AUTOSAR XML (schema 4-3-0)
package /App_NFC
  sender receiver interface IF_NFC  # NFC SWC Output
    data NFC_STR: type=IDT_NFC_STR
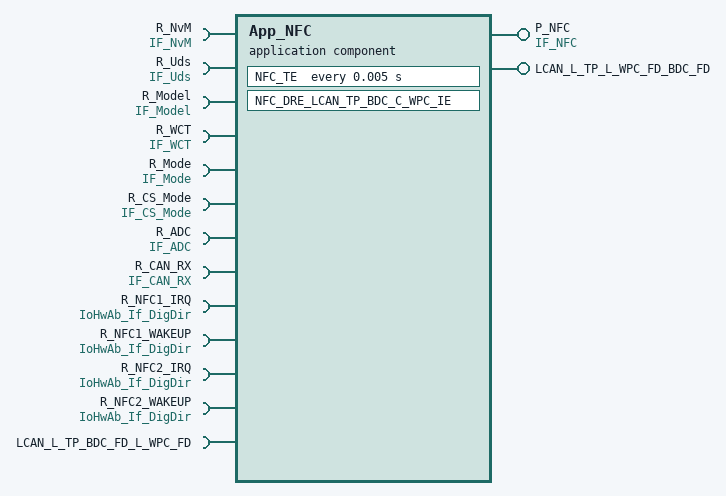
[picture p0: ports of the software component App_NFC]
  application sw component type App_NFC
    provide port P_NFC: nonqueued-sender-com-spec=NFC_STR, provided-interface=IF_NFC
    12 x require port:
      R_NvM: nonqueued-receiver-com-spec=NvM_STR, required-interface=IF_NvM
      R_Uds: nonqueued-receiver-com-spec=Uds_STR, required-interface=IF_Uds
      R_Model: nonqueued-receiver-com-spec=Model_STR, required-interface=IF_Model
      R_WCT: nonqueued-receiver-com-spec=WCT_STR, required-interface=IF_WCT
      R_Mode: nonqueued-receiver-com-spec=Mode_STR, required-interface=IF_Mode
      R_CS_Mode: required-com-specs=[ModeInit, NvMInit, ApplicationInit], required-interface=IF_CS_Mode
      R_ADC: nonqueued-receiver-com-spec=ADC_STR, required-interface=IF_ADC
      R_CAN_RX: nonqueued-receiver-com-spec=CAN_RX_STR, required-interface=IF_CAN_RX
      R_NFC1_IRQ: client-com-spec=ReadDirect, required-interface=IoHwAb_If_DigDir
      R_NFC1_WAKEUP: client-com-spec=WriteDirect, required-interface=IoHwAb_If_DigDir
      R_NFC2_IRQ: client-com-spec=ReadDirect, required-interface=IoHwAb_If_DigDir
      R_NFC2_WAKEUP: client-com-spec=WriteDirect, required-interface=IoHwAb_If_DigDir
    provide port LCAN_L_TP_L_WPC_FD_BDC_FD: queued-sender-com-spec{data-element=LCAN_L_TP_L_WPC_FD_BDC_FD_signal, network-representation=compu-method=ISignal_LCAN_L_TP_L_WPC_FD_BDC_FD_LCAN_L_TP_L_WPC_FD_BDC_FD_signal}, provided-interface=LCAN_L_TP_L_WPC_FD_BDC_FD
    require port LCAN_L_TP_BDC_FD_L_WPC_FD: queued-receiver-com-spec{data-element=LCAN_L_TP_BDC_FD_L_WPC_FD_signal, network-representation=compu-method=ISignal_LCAN_L_TP_BDC_FD_L_WPC_FD_LCAN_L_TP_BDC_FD_L_WPC_FD_signal, queue-length=1}, required-interface=LCAN_L_TP_BDC_FD_L_WPC_FD
    behavior InternalBehavior: data-type-mapping=DataTypeMappingSet_WPC
      data received event DRE_NFC_DRE_LCAN_TP_BDC_C_WPC_IE_LCAN_L_TP_BDC_FD_L_WPC_FD_LCAN_L_TP_BDC_FD_L_WPC_FD_signal: start-on-event=NFC_DRE_LCAN_TP_BDC_C_WPC_IE, data=LCAN_L_TP_BDC_FD_L_WPC_FD.LCAN_L_TP_BDC_FD_L_WPC_FD_signal
      timing event TE_NFC_TE: start-on-event=NFC_TE, period=0.005
      runnable NFC_TE: symbol=NFC_TE_Runnable
        data-receive-point-by-arguments:
          7 x access, all with scope=COMMUNICATION-INTER-ECU:
            DRPBA_NFC_TE_R_ADC_Structure: accessed-variable=R_ADC.ADC_STR
            DRPBA_NFC_TE_R_Mode_Structure: accessed-variable=R_Mode.Mode_STR
            DRPBA_NFC_TE_R_Model_Structure: accessed-variable=R_Model.Model_STR
            DRPBA_NFC_TE_R_BCAN_RX_BCAN_RX_STR: accessed-variable=R_CAN_RX.CAN_RX_STR
            DRPBA_NFC_TE_R_WCT_WCT_STR_ALL: accessed-variable=R_WCT.WCT_STR
            DRPBA_NFC_TE_R_Uds_Uds_STR: accessed-variable=R_Uds.Uds_STR
            DRPBA_NFC_TE_R_NvM_NvM_STR: accessed-variable=R_NvM.NvM_STR
        data-send-points:
          access DSP_NFC_TE_P_NFC_NFC2_STR: accessed-variable=P_NFC.NFC_STR, scope=COMMUNICATION-INTER-ECU
        7 x sync call:
          SSCP_NFC_TE_R_CS_Mode_ApplicationInit: operation=R_CS_Mode.ApplicationInit
          SSCP_NFC_TE_R_CS_Mode_ModeInit: operation=R_CS_Mode.ModeInit
          SSCP_NFC_TE_R_CS_Mode_NvMInit: operation=R_CS_Mode.NvMInit
          SSCP_NFC_TE_R_NFC1_IRQ_ReadDirect: operation=R_NFC1_IRQ.ReadDirect
          SSCP_NFC_TE_R_NFC1_WAKEUP_WriteDirect: operation=R_NFC1_WAKEUP.WriteDirect
          SSCP_NFC_TE_R_NFC2_IRQ_ReadDirect: operation=R_NFC2_IRQ.ReadDirect
          SSCP_NFC_TE_R_NFC2_WAKEUP_WriteDirect: operation=R_NFC2_WAKEUP.WriteDirect
      runnable NFC_DRE_LCAN_TP_BDC_C_WPC_IE: symbol=NFC_DRE_LCAN_TP_BDC_C_WPC_IE_Runnable
        data-receive-point-by-arguments:
          access DRPBA_NFC_DRE_LCAN_TP_BDC_C_WPC_IE_LCAN_L_TP_BDC_FD_L_WPC_FD_LCAN_L_TP_BDC_FD_L_WPC_FD_signal: accessed-variable=LCAN_L_TP_BDC_FD_L_WPC_FD.LCAN_L_TP_BDC_FD_L_WPC_FD_signal, scope=COMMUNICATION-INTER-ECU
        data-send-points:
          access DSP_NFC_DRE_LCAN_TP_BDC_C_WPC_IE_LCAN_L_TP_L_WPC_FD_BDC_FD_LCAN_L_TP_L_WPC_FD_BDC_FD_signal: accessed-variable=LCAN_L_TP_L_WPC_FD_BDC_FD.LCAN_L_TP_L_WPC_FD_BDC_FD_signal, scope=COMMUNICATION-INTER-ECU
